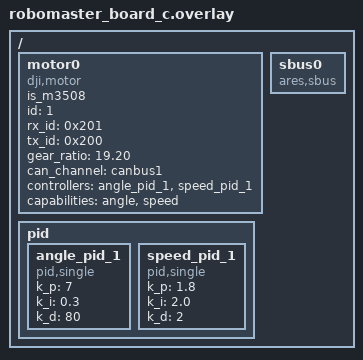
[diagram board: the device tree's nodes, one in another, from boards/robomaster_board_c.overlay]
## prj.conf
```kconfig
# 启用线程分析器
CONFIG_THREAD_ANALYZER=y
CONFIG_THREAD_ANALYZER_USE_LOG=y
CONFIG_THREAD_ANALYZER_USE_PRINTK=n
CONFIG_THREAD_NAME=y
# CONFIG_THREAD_ANALYZER_AUTO=y
# CONFIG_THREAD_ANALYZER_AUTO_INTERVAL=5
CONFIG_THREAD_ANALYZER_LOG_LEVEL_INF=y
CONFIG_THREAD_ANALYZER_AUTO_SEPARATE_CORES=n

# 启用 Shell 支持
CONFIG_SHELL=n
CONFIG_SHELL_BACKENDS=n
CONFIG_SHELL_BACKEND_SERIAL=n

# 启用 UART 控制台
CONFIG_UART_CONSOLE=y

# 禁用 SEGGER RTT
CONFIG_USE_SEGGER_RTT=n

# 启用事件支持
CONFIG_EVENTS=y

# 启用控制台支持
CONFIG_CONSOLE=y

# 启用日志系统
CONFIG_LOG=y
CONFIG_LOG_MODE_IMMEDIATE=y
CONFIG_LOG_PRINTK=y
CONFIG_LOG_BACKEND_UART=y
# CONFIG_LOG_MODE_IMMEDIATE=y

# 启用串行支持
CONFIG_SERIAL=y

# 禁用优化
CONFIG_NO_OPTIMIZATIONS=y
CONFIG_COMPILER_OPT=""

# 启用驱动
CONFIG_MOTOR=y
CONFIG_MOTOR_DJI=y
CONFIG_MOTOR_LOG_LEVEL=4
CONFIG_CAN=y
CONFIG_MOTOR_INIT_PRIORITY=90

CONFIG_ARES=y

# use ASYNC uart API
CONFIG_SERIAL=y
CONFIG_UART_ASYNC_API=y
CONFIG_UART_INTERRUPT_DRIVEN=y

CONFIG_DMA=y
CONFIG_DMA_STM32=y  # STM32 DMA 驱动
CONFIG_UART_STM32=y # STM32 UART 驱动
# CONFIG_STM32_UART_DMA=y

# CONFIG_HAS_STM32CUBE=y
# CONFIG_USE_STM32_HAL_DMA=y
CONFIG_SPI=y
CONFIG_SPI_STM32=y

CONFIG_DEBUG=y
```

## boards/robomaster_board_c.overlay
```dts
/ {
	motor0: motor0{
		compatible = "dji,motor";
		is_m3508;
		id = <1>;
		rx_id = <0x201>;
		tx_id = <0x200>;
		gear_ratio = "19.20";
		status = "okay";
		can_channel = <&canbus1>;
		controllers = <&angle_pid_1 &speed_pid_1>;
		capabilities = "angle", "speed";
	};

	pid {
		angle_pid_1: angle_pid_1 {
			#controller-cells = <0>;
			compatible = "pid,single";
			k_p = "7";
			k_i = "0.3";
			k_d = "80";
		};
		speed_pid_1: speed_pid_1 {
			#controller-cells = <0>;
			compatible = "pid,single";
			k_p = "1.8";
			k_i = "2.0";
			k_d = "2";
		};
	};
	sbus0: sbus0 {
		compatible = "ares,sbus";
		status = "okay";
	};
};
```

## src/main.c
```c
/*
 * Copyright (c) 2024 ttwards <12411711@mail.sustech.edu.cn>
 *
 * SPDX-License-Identifier: Apache-2.0
 */

#include <stddef.h>
#include <stdint.h>
#include <zephyr/device.h>
#include <zephyr/logging/log.h>
#include <zephyr/devicetree.h>
#include <zephyr/drivers/can.h>
#include <zephyr/debug/thread_analyzer.h>
#include <zephyr/kernel.h>
#include <zephyr/sys/printk.h>
#include <zephyr/drivers/motor.h>
#include <ares/board/init.c>

LOG_MODULE_REGISTER(main, LOG_LEVEL_DBG);

#define HIGH_BYTE(x)           ((x) >> 8)
#define LOW_BYTE(x)            ((x) & 0xFF)
#define COMBINE_HL8(HIGH, LOW) ((HIGH << 8) + LOW)

/* Devicetree */
#define CANBUS_NODE DT_CHOSEN(zephyr_canbus)
#define CAN1_NODE   DT_INST(0, vnd_canbus)
#define MOTOR1_NODE DT_INST(0, dji_motor)

#define FEEDBACK_STACK_SIZE 1536

const struct device *can_dev = DEVICE_DT_GET(CANBUS_NODE);
const struct device *motor1 = DEVICE_DT_GET(MOTOR1_NODE);

/* CAN Feedback to console*/
void console_feedback(void *arg1, void *arg2, void *arg3)
{
	while (1) {
		LOG_INF("rpm: motor1: %.2f\n", (double)motor_get_speed(motor1));
		k_msleep(500);
	}
}
K_THREAD_DEFINE(feedback_thread, FEEDBACK_STACK_SIZE, console_feedback, NULL, NULL, NULL, 1, 0,
		100);

int main(void)
{
	board_init();

	motor_control(motor1, ENABLE_MOTOR);
	motor_set_speed(motor1, 500);

	while (1) {
		k_msleep(1500);
	}
}
```
